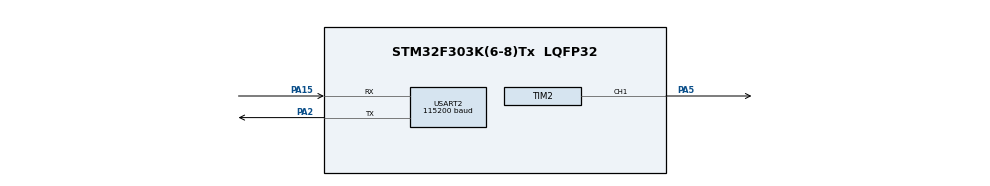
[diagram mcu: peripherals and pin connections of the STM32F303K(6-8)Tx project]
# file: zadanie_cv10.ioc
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Dma.Request0=USART2_RX
Dma.Request1=USART2_TX
Dma.USART2_RX.0.Direction=DMA_PERIPH_TO_MEMORY
Dma.USART2_RX.0.Instance=DMA1_Channel6
Dma.USART2_RX.0.MemDataAlignment=DMA_MDATAALIGN_BYTE
Dma.USART2_RX.0.MemInc=DMA_MINC_ENABLE
Dma.USART2_RX.0.Mode=DMA_NORMAL
Dma.USART2_RX.0.PeriphDataAlignment=DMA_PDATAALIGN_BYTE
Dma.USART2_RX.0.PeriphInc=DMA_PINC_DISABLE
Dma.USART2_RX.0.Priority=DMA_PRIORITY_LOW
Dma.USART2_TX.1.Direction=DMA_MEMORY_TO_PERIPH
Dma.USART2_TX.1.Instance=DMA1_Channel7
Dma.USART2_TX.1.MemDataAlignment=DMA_MDATAALIGN_BYTE
Dma.USART2_TX.1.MemInc=DMA_MINC_ENABLE
Dma.USART2_TX.1.Mode=DMA_NORMAL
Dma.USART2_TX.1.PeriphDataAlignment=DMA_PDATAALIGN_BYTE
Dma.USART2_TX.1.PeriphInc=DMA_PINC_DISABLE
Dma.USART2_TX.1.Priority=DMA_PRIORITY_LOW
Mcu.Family=STM32F3
Mcu.Name=STM32F303K(6-8)Tx
Mcu.Package=LQFP32
NVIC.DMA1_Channel6_IRQn=true\:0\:0\:false\:false\:true\:false\:true
NVIC.DMA1_Channel7_IRQn=true\:0\:0\:false\:false\:true\:false\:true
NVIC.PriorityGroup=NVIC_PRIORITYGROUP_4
NVIC.TIM2_IRQn=true\:0\:0\:false\:false\:true\:true\:true
NVIC.USART2_IRQn=true\:0\:0\:false\:false\:true\:true\:true
PA15.Mode=Asynchronous
PA15.Signal=USART2_RX
PA2.Mode=Asynchronous
PA2.Signal=USART2_TX
PA5.Signal=S_TIM2_CH1_ETR
ProjectManager.HeapSize=0x200
ProjectManager.StackSize=0x400
ProjectManager.TargetToolchain=STM32CubeIDE
RCC.AHBFreq_Value=8000000
RCC.APB1Freq_Value=8000000
RCC.APB2Freq_Value=8000000
RCC.CortexFreq_Value=8000000
RCC.HSE_VALUE=8000000
RCC.HSI_VALUE=8000000
RCC.SYSCLKFreq_VALUE=8000000
SH.S_TIM2_CH1_ETR.0=TIM2_CH1,PWM Generation1 CH1
TIM2.AutoReloadPreload=TIM_AUTORELOAD_PRELOAD_DISABLE
TIM2.Channel-Output\ Compare2\ No\ Output=TIM_CHANNEL_2
TIM2.Channel-PWM\ Generation1\ CH1=TIM_CHANNEL_1
TIM2.OC1Preload_PWM=DISABLE
TIM2.OCMode_2=TIM_OCMODE_ACTIVE
TIM2.Period=99
TIM2.Prescaler=799
TIM2.Pulse-PWM\ Generation1\ CH1=50
USART2.BaudRate=115200
USART2.VirtualMode-Asynchronous=VM_ASYNC
VP_TIM2_VS_ClockSourceINT.Mode=Internal
VP_TIM2_VS_no_output2.Mode=Output Compare2 No Output
board=custom

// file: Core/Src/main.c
/* USER CODE BEGIN Header */
/**
  ******************************************************************************
  * @file           : main.c
  * @brief          : Main program body
  ******************************************************************************
  * @attention
  *
  * <h2><center>&copy; Copyright (c) 2020 STMicroelectronics.
  * All rights reserved.</center></h2>
  *
  * This software component is licensed by ST under BSD 3-Clause license,
  * the "License"; You may not use this file except in compliance with the
  * License. You may obtain a copy of the License at:
  *                        opensource.org/licenses/BSD-3-Clause
  *
  ******************************************************************************
  */
/* USER CODE END Header */
#include "main.h"
#include "dma.h"
#include "tim.h"
#include "usart.h"
#include "gpio.h"

/* USER CODE BEGIN PV */
uint8_t currentDutyCycle = 50;
uint8_t targetDutyCycle = 50;
uint8_t programMode = AUTO_MODE;
uint8_t DutyCycleTrend = INCREASING_TREND;
char manualString[] = "manual";
char autoString[] = "auto";
char pwmString[] = "PWM";

/* USER CODE END PV */

void SystemClock_Config(void);
/* USER CODE BEGIN PFP */
void proccesDmaData(char *paket,uint16_t length);
uint8_t extractDataString(char *paket, uint16_t *length);
void executeInstruction(char *instruction,uint16_t length);
uint8_t compareString(char *string1,char *string2,uint16_t dataLength);
void executePWMinstruction(char *instruction,uint16_t length);
uint16_t string2int(char *string, uint8_t length);
uint16_t nonNegativePower(uint16_t base, uint8_t exponent);

void updateCurrentDutyCycle(void);
void setCurrentDutyCycle(uint8_t new_currentDutyCycle);
void autoModeUpdateTargetDutyCycle(void);
void setTargetDutyCycleAndTrend(uint8_t desiredDutyCycle);
uint8_t determineCurrentDutyCycle(void);
/* USER CODE END PFP */

int main(void)
{

  /* MCU Configuration--------------------------------------------------------*/

  /* Reset of all peripherals, Initializes the Flash interface and the Systick. */

  LL_APB2_GRP1_EnableClock(LL_APB2_GRP1_PERIPH_SYSCFG);
  LL_APB1_GRP1_EnableClock(LL_APB1_GRP1_PERIPH_PWR);

  NVIC_SetPriorityGrouping(NVIC_PRIORITYGROUP_4);

  /* System interrupt init*/

  /* Configure the system clock */
  SystemClock_Config();

  /* Initialize all configured peripherals */
  MX_GPIO_Init();
  MX_DMA_Init();
  MX_USART2_UART_Init();
  MX_TIM2_Init();
  /* USER CODE BEGIN 2 */
  USART2_RegisterCallback(proccesDmaData);
  TIM2_RegisterCallback(determineCurrentDutyCycle);
  /* USER CODE END 2 */

  /* Infinite loop */
  while (1)
  {

  }
}

void SystemClock_Config(void)
{
  LL_FLASH_SetLatency(LL_FLASH_LATENCY_0);
  while(LL_FLASH_GetLatency()!= LL_FLASH_LATENCY_0)
  {
  }
  LL_RCC_HSI_Enable();

   /* Wait till HSI is ready */
  while(LL_RCC_HSI_IsReady() != 1)
  {

  }
  LL_RCC_HSI_SetCalibTrimming(16);
  LL_RCC_SetAHBPrescaler(LL_RCC_SYSCLK_DIV_1);
  LL_RCC_SetAPB1Prescaler(LL_RCC_APB1_DIV_1);
  LL_RCC_SetAPB2Prescaler(LL_RCC_APB1_DIV_1);
  LL_RCC_SetSysClkSource(LL_RCC_SYS_CLKSOURCE_HSI);

   /* Wait till System clock is ready */
  while(LL_RCC_GetSysClkSource() != LL_RCC_SYS_CLKSOURCE_STATUS_HSI)
  {

  }
  LL_Init1msTick(8000000);
  LL_SetSystemCoreClock(8000000);
}

/* USER CODE BEGIN 4 */
/*
 * Implementation of function processing data received via USART.
 */
void proccesDmaData(char *paket,uint16_t length){
	if(extractDataString(paket, &length) != 0){
		return;
	}
	else{
		executeInstruction(paket,length);
	}
}

uint8_t extractDataString(char *paket, uint16_t *length_ptr){
	uint16_t length = *length_ptr;
	if(paket[length-1] == '\r'){
		length -= 1;
	}
	if(length <= 2){
		return -1;
	}
	if((paket[0] == '$') && (paket[length-1] == '$')){
		for(int i = 0; i < (length - 2); i++){
			paket[i] = paket[i+1];
		}
		paket[length-2] = '\0';
		*length_ptr = length - 2; //length without '\0'
		return 0;
	}
	else return -1;
}

void executeInstruction(char *instruction,uint16_t length){
	if(programMode == MANUAL_MODE){
		executePWMinstruction(instruction, length);
	}

	if(compareString(instruction, manualString, length) == 0){
		programMode = MANUAL_MODE;
	}

	if(compareString(instruction, autoString, length) == 0){
			programMode = AUTO_MODE;
	}
}

uint8_t compareString(char *string1,char *string2,uint16_t dataLength){
	for(int i = 0; i < dataLength; i++){
		if(string1[i] != string2[i]){
			return -1;
		}
	}
	return 0;
}

void executePWMinstruction(char *instruction,uint16_t length){
	/* PWMinstructions PWMxx consists of 2 parts:
	 * 1) pwmString : PWM
	 * 2) dutyCycleStr : xx
	 */
	static int dutyCycleStrLen = 2;
	int pwmInstructionSize = sizeof(pwmString) -1 + dutyCycleStrLen; // 2 chars are numbers representing Duty cycle, 1 char is '\0' in pwmString

	if(length != pwmInstructionSize) return;

	if(compareString(instruction, pwmString, length - dutyCycleStrLen) != 0) return;

	for(int i = (sizeof(pwmString) -1); i < pwmInstructionSize; i++){
		if((instruction[i] < '0') || (instruction[i] > '9')){
				return;
		}
	}

	setTargetDutyCycleAndTrend( string2int(instruction + sizeof(pwmString) - 1, dutyCycleStrLen));
}

uint16_t string2int(char *string, uint8_t length){
	uint16_t value = 0;
	for(int i = 0; i < length; i++){
		value += (string[i] - '0') * nonNegativePower(10,length-i-1);
	}
	return value;
}

uint16_t nonNegativePower(uint16_t base, uint8_t exponent){
	int value = 1;

	if(exponent == 0){
		return 1;
	}

	for(int i = 1; i <= exponent; i++){
		value *= base;
	}
	return value;
}

void updateCurrentDutyCycle(void){
	if(targetDutyCycle > currentDutyCycle){
		setCurrentDutyCycle(currentDutyCycle + UPTREND_STEP);
	}
	else if(targetDutyCycle < currentDutyCycle){
		setCurrentDutyCycle(currentDutyCycle - DOWNTREND_STEP);
	}
}

void setCurrentDutyCycle(uint8_t new_currentDutyCycle){
	if(new_currentDutyCycle >= MAX_DUTY_CYCLE){
		currentDutyCycle = MAX_DUTY_CYCLE;
	}
	else if(new_currentDutyCycle <= MIN_DUTY_CYCLE){
		currentDutyCycle = MIN_DUTY_CYCLE;
	}
	else{
		currentDutyCycle = new_currentDutyCycle;
	}
}

void autoModeUpdateTargetDutyCycle(void){
	if(DutyCycleTrend == INCREASING_TREND){
		setTargetDutyCycleAndTrend(targetDutyCycle + UPTREND_STEP);
	}
	else{
		setTargetDutyCycleAndTrend(targetDutyCycle - DOWNTREND_STEP);
	}
}

void setTargetDutyCycleAndTrend(uint8_t desiredDutyCycle){
	if(desiredDutyCycle >= MAX_DUTY_CYCLE){
			targetDutyCycle = MAX_DUTY_CYCLE;
			DutyCycleTrend = DECREASING_TREND;
	}
	else if(desiredDutyCycle <= MIN_DUTY_CYCLE){
			targetDutyCycle = MIN_DUTY_CYCLE;
			DutyCycleTrend = INCREASING_TREND;
	}
	else{
		targetDutyCycle = desiredDutyCycle;
	}
}

uint8_t determineCurrentDutyCycle(void){
	if(programMode == AUTO_MODE){
		autoModeUpdateTargetDutyCycle();
	}
	updateCurrentDutyCycle();
	return currentDutyCycle;
}

/* USER CODE END 4 */

void Error_Handler(void)
{
}

/************************ (C) COPYRIGHT STMicroelectronics *****END OF FILE****/
